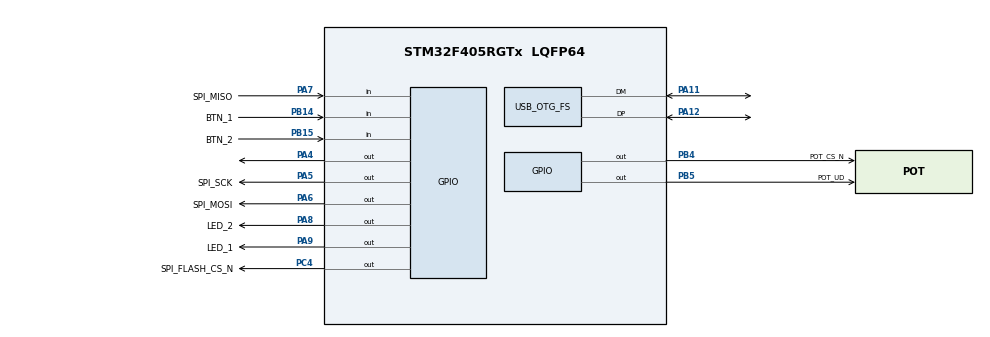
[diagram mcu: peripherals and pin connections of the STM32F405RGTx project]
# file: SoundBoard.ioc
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Mcu.Family=STM32F4
Mcu.Name=STM32F405RGTx
Mcu.Package=LQFP64
NVIC.OTG_FS_IRQn=true\:0\:0\:false\:false\:true\:false\:true
NVIC.PriorityGroup=NVIC_PRIORITYGROUP_4
NVIC.TIM3_IRQn=true\:0\:0\:false\:false\:true\:true\:true
PA11.Mode=Device_Only
PA11.Signal=USB_OTG_FS_DM
PA12.Mode=Device_Only
PA12.Signal=USB_OTG_FS_DP
PA13.Signal=SYS_JTMS-SWDIO
PA14.Signal=SYS_JTCK-SWCLK
PA4.Signal=GPIO_Output
PA5.GPIO_Label=SPI_SCK
PA5.Signal=GPIO_Output
PA6.GPIO_Label=SPI_MOSI
PA6.Signal=GPIO_Output
PA7.GPIO_Label=SPI_MISO
PA7.Signal=GPIO_Input
PA8.GPIO_Label=LED_2
PA8.Signal=GPIO_Output
PA9.GPIO_Label=LED_1
PA9.Signal=GPIO_Output
PB14.GPIO_Label=BTN_1
PB14.Signal=GPIO_Input
PB15.GPIO_Label=BTN_2
PB15.Signal=GPIO_Input
PB4.GPIO_Label=POT_CS_N
PB4.Signal=GPIO_Output
PB5.GPIO_Label=POT_UD
PB5.Signal=GPIO_Output
PC4.GPIO_Label=SPI_FLASH_CS_N
PC4.Signal=GPIO_Output
PH0-OSC_IN.Mode=HSE-External-Oscillator
PH0-OSC_IN.Signal=RCC_OSC_IN
PH1-OSC_OUT.Mode=HSE-External-Oscillator
PH1-OSC_OUT.Signal=RCC_OSC_OUT
ProjectManager.HeapSize=0x200
ProjectManager.StackSize=0x400
ProjectManager.TargetToolchain=STM32CubeIDE
RCC.48MHZClocksFreq_Value=48000000
RCC.AHBFreq_Value=25000000
RCC.APB1Freq_Value=25000000
RCC.APB1TimFreq_Value=25000000
RCC.APB2Freq_Value=25000000
RCC.APB2TimFreq_Value=25000000
RCC.CortexFreq_Value=25000000
RCC.HCLKFreq_Value=25000000
RCC.HSE_VALUE=25000000
RCC.HSI_VALUE=16000000
RCC.LSE_VALUE=32768
RCC.PLLM=15
RCC.PLLN=144
RCC.PLLQ=5
RCC.SYSCLKFreq_VALUE=25000000
RCC.SYSCLKSource=RCC_SYSCLKSOURCE_HSE
RCC.VCOOutputFreq_Value=240000000
USB_DEVICE.CLASS_NAME_FS=CDC
USB_DEVICE.VirtualMode-CDC_FS=Cdc
USB_DEVICE.VirtualModeFS=Cdc_FS
USB_OTG_FS.VirtualMode=Device_Only
VP_TIM3_VS_ClockSourceINT.Mode=Internal
VP_TIM3_VS_ClockSourceITR.Mode=TriggerSource_ITR0
VP_USB_DEVICE_VS_USB_DEVICE_CDC_FS.Mode=CDC_FS
board=custom

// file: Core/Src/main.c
/* USER CODE BEGIN Header */
/**
  ******************************************************************************
  * @file           : main.c
  * @brief          : Main program body
  ******************************************************************************
  * @attention
  *
  * <h2><center>&copy; Copyright (c) 2020 STMicroelectronics.
  * All rights reserved.</center></h2>
  *
  * This software component is licensed by ST under BSD 3-Clause license,
  * the "License"; You may not use this file except in compliance with the
  * License. You may obtain a copy of the License at:
  *                        opensource.org/licenses/BSD-3-Clause
  *
  ******************************************************************************
  */
/* USER CODE END Header */

#include "main.h"
#include "usb_device.h"

TIM_HandleTypeDef htim3;

void SystemClock_Config(void);
static void MX_GPIO_Init(void);
static void MX_TIM3_Init(void);

int main(void)
{
  /* USER CODE BEGIN 1 */
  uint8_t data = 0;
  /* USER CODE END 1 */

  /* MCU Configuration--------------------------------------------------------*/

  /* Reset of all peripherals, Initializes the Flash interface and the Systick. */
  HAL_Init();

  /* Configure the system clock */
  SystemClock_Config();

  /* Initialize all configured peripherals */
  MX_GPIO_Init();
  MX_USB_DEVICE_Init();
  MX_TIM3_Init();

  /* Infinite loop */
  while (1)
  {

    /* USER CODE BEGIN 3 */

	  for(int i = 0; i < 25 * 1000; i++)
	  {}

	  HAL_GPIO_TogglePin(GPIOA, GPIO_PIN_4);

  }
  /* USER CODE END 3 */
}

void SystemClock_Config(void)
{
  LL_FLASH_SetLatency(LL_FLASH_LATENCY_0);

  if(LL_FLASH_GetLatency() != LL_FLASH_LATENCY_0)
  {
  Error_Handler();
  }
  LL_PWR_SetRegulVoltageScaling(LL_PWR_REGU_VOLTAGE_SCALE1);
  LL_RCC_HSE_Enable();

   /* Wait till HSE is ready */
  while(LL_RCC_HSE_IsReady() != 1)
  {

  }
  LL_RCC_PLL_ConfigDomain_48M(LL_RCC_PLLSOURCE_HSE, LL_RCC_PLLM_DIV_15, 144, LL_RCC_PLLQ_DIV_5);
  LL_RCC_PLL_Enable();

   /* Wait till PLL is ready */
  while(LL_RCC_PLL_IsReady() != 1)
  {

  }
  LL_RCC_SetAHBPrescaler(LL_RCC_SYSCLK_DIV_1);
  LL_RCC_SetAPB1Prescaler(LL_RCC_APB1_DIV_1);
  LL_RCC_SetAPB2Prescaler(LL_RCC_APB2_DIV_1);
  LL_RCC_SetSysClkSource(LL_RCC_SYS_CLKSOURCE_HSE);

   /* Wait till System clock is ready */
  while(LL_RCC_GetSysClkSource() != LL_RCC_SYS_CLKSOURCE_STATUS_HSE)
  {

  }
  LL_SetSystemCoreClock(25000000);

   /* Update the time base */
  if (HAL_InitTick (TICK_INT_PRIORITY) != HAL_OK)
  {
    Error_Handler();
  };
}

static void MX_TIM3_Init(void)
{

  TIM_ClockConfigTypeDef sClockSourceConfig = {0};
  TIM_SlaveConfigTypeDef sSlaveConfig = {0};
  TIM_MasterConfigTypeDef sMasterConfig = {0};

  htim3.Instance = TIM3;
  htim3.Init.Prescaler = 0;
  htim3.Init.CounterMode = TIM_COUNTERMODE_UP;
  htim3.Init.Period = 0;
  htim3.Init.ClockDivision = TIM_CLOCKDIVISION_DIV1;
  htim3.Init.AutoReloadPreload = TIM_AUTORELOAD_PRELOAD_DISABLE;
  if (HAL_TIM_Base_Init(&htim3) != HAL_OK)
  {
    Error_Handler();
  }
  sClockSourceConfig.ClockSource = TIM_CLOCKSOURCE_INTERNAL;
  if (HAL_TIM_ConfigClockSource(&htim3, &sClockSourceConfig) != HAL_OK)
  {
    Error_Handler();
  }
  sSlaveConfig.SlaveMode = TIM_SLAVEMODE_DISABLE;
  sSlaveConfig.InputTrigger = TIM_TS_ITR0;
  if (HAL_TIM_SlaveConfigSynchro(&htim3, &sSlaveConfig) != HAL_OK)
  {
    Error_Handler();
  }
  sMasterConfig.MasterOutputTrigger = TIM_TRGO_RESET;
  sMasterConfig.MasterSlaveMode = TIM_MASTERSLAVEMODE_DISABLE;
  if (HAL_TIMEx_MasterConfigSynchronization(&htim3, &sMasterConfig) != HAL_OK)
  {
    Error_Handler();
  }

}

static void MX_GPIO_Init(void)
{
  LL_GPIO_InitTypeDef GPIO_InitStruct = {0};

  /* GPIO Ports Clock Enable */
  LL_AHB1_GRP1_EnableClock(LL_AHB1_GRP1_PERIPH_GPIOH);
  LL_AHB1_GRP1_EnableClock(LL_AHB1_GRP1_PERIPH_GPIOA);
  LL_AHB1_GRP1_EnableClock(LL_AHB1_GRP1_PERIPH_GPIOC);
  LL_AHB1_GRP1_EnableClock(LL_AHB1_GRP1_PERIPH_GPIOB);

  /**/
  LL_GPIO_ResetOutputPin(GPIOA, LL_GPIO_PIN_4|SPI_SCK_Pin|SPI_MOSI_Pin|LED_2_Pin
                          |LED_1_Pin);

  /**/
  LL_GPIO_ResetOutputPin(SPI_FLASH_CS_N_GPIO_Port, SPI_FLASH_CS_N_Pin);

  /**/
  LL_GPIO_ResetOutputPin(GPIOB, POT_CS_N_Pin|POT_UD_Pin);

  /**/
  GPIO_InitStruct.Pin = LL_GPIO_PIN_4|SPI_SCK_Pin|SPI_MOSI_Pin|LED_2_Pin
                          |LED_1_Pin;
  GPIO_InitStruct.Mode = LL_GPIO_MODE_OUTPUT;
  GPIO_InitStruct.Speed = LL_GPIO_SPEED_FREQ_LOW;
  GPIO_InitStruct.OutputType = LL_GPIO_OUTPUT_PUSHPULL;
  GPIO_InitStruct.Pull = LL_GPIO_PULL_NO;
  LL_GPIO_Init(GPIOA, &GPIO_InitStruct);

  /**/
  GPIO_InitStruct.Pin = SPI_MISO_Pin;
  GPIO_InitStruct.Mode = LL_GPIO_MODE_INPUT;
  GPIO_InitStruct.Pull = LL_GPIO_PULL_NO;
  LL_GPIO_Init(SPI_MISO_GPIO_Port, &GPIO_InitStruct);

  /**/
  GPIO_InitStruct.Pin = SPI_FLASH_CS_N_Pin;
  GPIO_InitStruct.Mode = LL_GPIO_MODE_OUTPUT;
  GPIO_InitStruct.Speed = LL_GPIO_SPEED_FREQ_LOW;
  GPIO_InitStruct.OutputType = LL_GPIO_OUTPUT_PUSHPULL;
  GPIO_InitStruct.Pull = LL_GPIO_PULL_NO;
  LL_GPIO_Init(SPI_FLASH_CS_N_GPIO_Port, &GPIO_InitStruct);

  /**/
  GPIO_InitStruct.Pin = BTN_1_Pin|BTN_2_Pin;
  GPIO_InitStruct.Mode = LL_GPIO_MODE_INPUT;
  GPIO_InitStruct.Pull = LL_GPIO_PULL_NO;
  LL_GPIO_Init(GPIOB, &GPIO_InitStruct);

  /**/
  GPIO_InitStruct.Pin = POT_CS_N_Pin|POT_UD_Pin;
  GPIO_InitStruct.Mode = LL_GPIO_MODE_OUTPUT;
  GPIO_InitStruct.Speed = LL_GPIO_SPEED_FREQ_LOW;
  GPIO_InitStruct.OutputType = LL_GPIO_OUTPUT_PUSHPULL;
  GPIO_InitStruct.Pull = LL_GPIO_PULL_NO;
  LL_GPIO_Init(GPIOB, &GPIO_InitStruct);

}

void Error_Handler(void)
{
}

/************************ (C) COPYRIGHT STMicroelectronics *****END OF FILE****/
